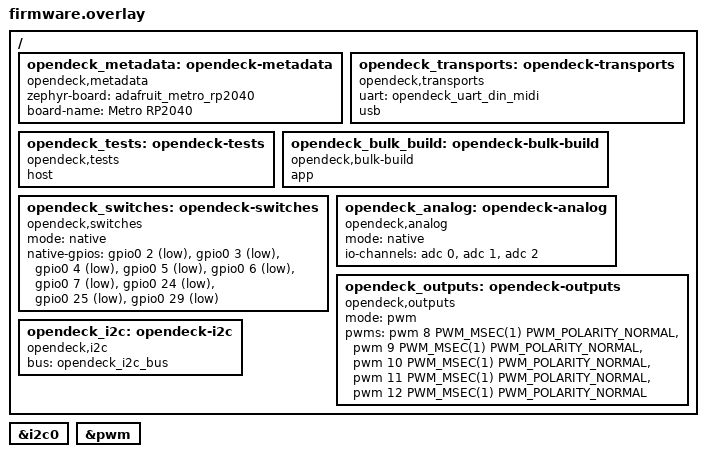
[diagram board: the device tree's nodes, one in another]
#include <zephyr/dt-bindings/pwm/pwm.h>

/ {
    opendeck_metadata: opendeck-metadata {
        compatible = "opendeck,metadata";
        zephyr-board = "adafruit_metro_rp2040";
        board-name = "Metro RP2040";
    };

    opendeck_transports: opendeck-transports {
        compatible = "opendeck,transports";
        uart = <&opendeck_uart_din_midi>;
        usb;
    };

    opendeck_tests: opendeck-tests {
        compatible = "opendeck,tests";
        host;
    };

    opendeck_bulk_build: opendeck-bulk-build {
        compatible = "opendeck,bulk-build";
        app;
    };

    opendeck_switches: opendeck-switches {
        compatible = "opendeck,switches";
        mode = "native";
        native-gpios =
            <&gpio0 2 (GPIO_PULL_UP | GPIO_ACTIVE_LOW)>,
            <&gpio0 3 (GPIO_PULL_UP | GPIO_ACTIVE_LOW)>,
            <&gpio0 4 (GPIO_PULL_UP | GPIO_ACTIVE_LOW)>,
            <&gpio0 5 (GPIO_PULL_UP | GPIO_ACTIVE_LOW)>,
            <&gpio0 6 (GPIO_PULL_UP | GPIO_ACTIVE_LOW)>,
            <&gpio0 7 (GPIO_PULL_UP | GPIO_ACTIVE_LOW)>,
            <&gpio0 24 (GPIO_PULL_UP | GPIO_ACTIVE_LOW)>,
            <&gpio0 25 (GPIO_PULL_UP | GPIO_ACTIVE_LOW)>,
            <&gpio0 29 (GPIO_PULL_UP | GPIO_ACTIVE_LOW)>;
    };

    opendeck_analog: opendeck-analog {
        compatible = "opendeck,analog";
        mode = "native";
        io-channels =
            <&adc 0>,
            <&adc 1>,
            <&adc 2>;
    };

    opendeck_outputs: opendeck-outputs {
        compatible = "opendeck,outputs";
        mode = "pwm";
        pwms =
            <&pwm 8 PWM_MSEC(1) PWM_POLARITY_NORMAL>,
            <&pwm 9 PWM_MSEC(1) PWM_POLARITY_NORMAL>,
            <&pwm 10 PWM_MSEC(1) PWM_POLARITY_NORMAL>,
            <&pwm 11 PWM_MSEC(1) PWM_POLARITY_NORMAL>,
            <&pwm 12 PWM_MSEC(1) PWM_POLARITY_NORMAL>;
    };

    opendeck_i2c: opendeck-i2c {
        compatible = "opendeck,i2c";
        bus = <&opendeck_i2c_bus>;
    };
};

&i2c0 {
    status = "okay";
};

&pwm {
    status = "okay";
};
